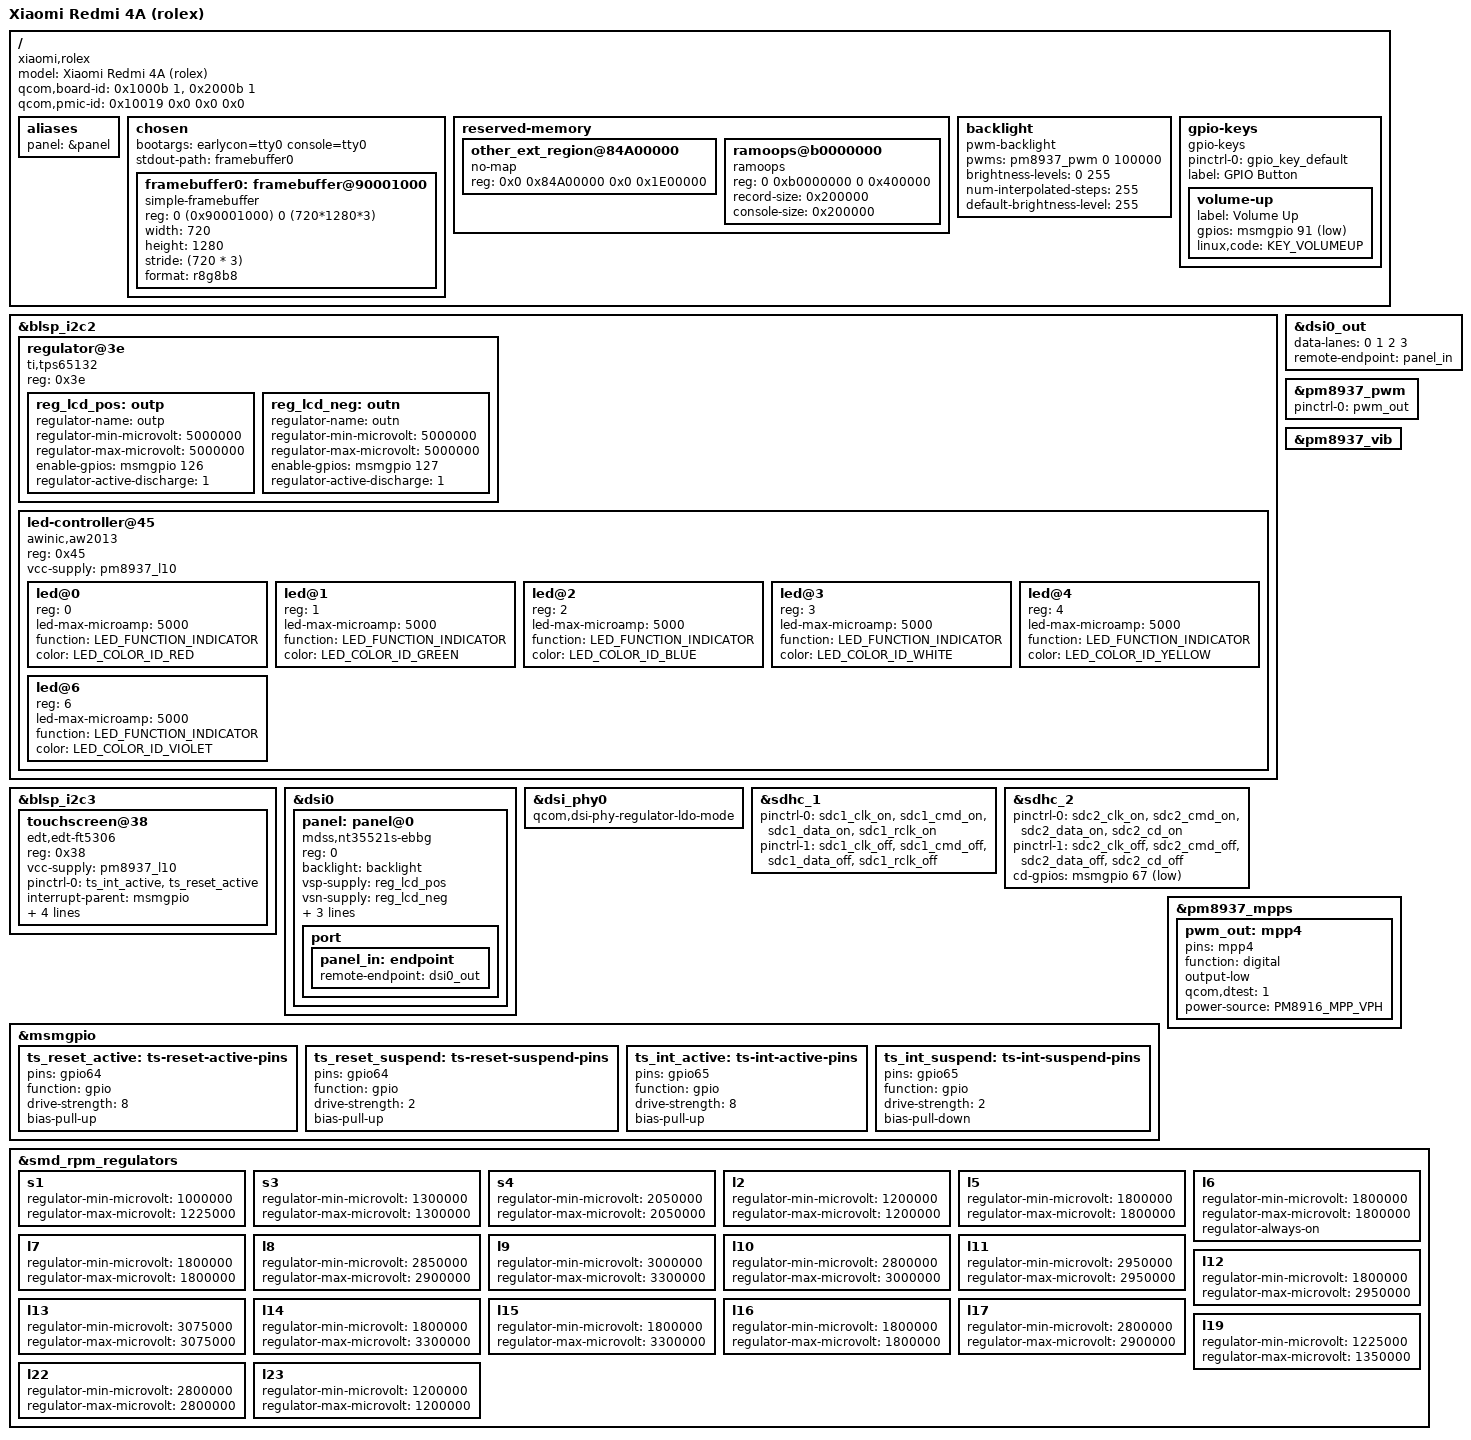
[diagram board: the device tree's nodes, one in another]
/dts-v1/;

#include "msm8917-pm8937.dtsi"
#include <dt-bindings/gpio/gpio.h>
#include <dt-bindings/leds/common.h>
#include <dt-bindings/pinctrl/qcom,pmic-mpp.h>

/ {
	model = "Xiaomi Redmi 4A (rolex)";
	compatible = "xiaomi,rolex", "qcom,msm8917";

	qcom,board-id= <0x1000b 1>, <0x2000b 1>;
	qcom,pmic-id = <0x10019 0x0 0x0 0x0>;

	aliases {
		panel = &panel;
	};

	chosen {
		bootargs = "earlycon=tty0 console=tty0";
		#address-cells = <2>;
		#size-cells = <2>;
		ranges;
		stdout-path = "framebuffer0";
		framebuffer0: framebuffer@90001000 {
			compatible = "simple-framebuffer";
			reg = <0 (0x90001000) 0 (720*1280*3)>;
			width = <720>;
			height = <1280>;
			stride = <(720 * 3)>;
			format = "r8g8b8";
			status= "okay";
		};
	};

	reserved-memory {
		/delete-node/other_ext_region@85b00000;

		other_ext_region@84A00000 {
			no-map;
			reg = <0x0 0x84A00000 0x0 0x1E00000>;
		};

		ramoops@b0000000 {
			compatible = "ramoops";
			reg = <0 0xb0000000 0 0x400000>;
			record-size = <0x200000>;
			console-size = <0x200000>;
		};
	};

	backlight: backlight {
		compatible = "pwm-backlight";
		pwms = <&pm8937_pwm 0 100000>;

		brightness-levels = <0 255>;
		num-interpolated-steps = <255>;
		default-brightness-level = <255>;
	};

	gpio-keys {
		compatible = "gpio-keys";

		pinctrl-names = "default";
		pinctrl-0 = <&gpio_key_default>;

		label = "GPIO Button";

		volume-up {
			label = "Volume Up";
			gpios = <&msmgpio 91 GPIO_ACTIVE_LOW>;
			linux,code = <KEY_VOLUMEUP>;
		};
	};
};

&blsp_i2c2 {
	status = "okay";
	regulator@3e {
		compatible = "ti,tps65132";
		reg = <0x3e>;

		//pinctrl-names = "default";
		//pinctrl-0 = <&reg_lcd_en_default>;

		reg_lcd_pos: outp {
			regulator-name = "outp";
			regulator-min-microvolt = <5000000>;
			regulator-max-microvolt = <5000000>;
			enable-gpios = <&msmgpio 126 GPIO_ACTIVE_HIGH>;
			regulator-active-discharge = <1>;
		};

		reg_lcd_neg: outn {
			regulator-name = "outn";
			regulator-min-microvolt = <5000000>;
			regulator-max-microvolt = <5000000>;
			enable-gpios = <&msmgpio 127 GPIO_ACTIVE_HIGH>;
			regulator-active-discharge = <1>;
		};
	};

	led-controller@45 {
		#address-cells = <1>;
		#size-cells = <0>;

		compatible = "awinic,aw2013";

		reg = <0x45>;

		vcc-supply = <&pm8937_l10>;

		led@0 {
			reg = <0>;
			led-max-microamp = <5000>;
			function = LED_FUNCTION_INDICATOR;
			color = <LED_COLOR_ID_RED>;
		};
		led@1 {
			reg = <1>;
			led-max-microamp = <5000>;
			function = LED_FUNCTION_INDICATOR;
			color = <LED_COLOR_ID_GREEN>;
		};
		led@2 {
			reg = <2>;
			led-max-microamp = <5000>;
			function = LED_FUNCTION_INDICATOR;
			color = <LED_COLOR_ID_BLUE>;
		};
		led@3 {
			reg = <3>;
			led-max-microamp = <5000>;
			function = LED_FUNCTION_INDICATOR;
			color = <LED_COLOR_ID_WHITE>;
		};

		led@4 {
			reg = <4>;
			led-max-microamp = <5000>;
			function = LED_FUNCTION_INDICATOR;
			color = <LED_COLOR_ID_YELLOW>;
		};
/*
		led@5 {
			reg = <5>;
			led-max-microamp = <5000>;
			function = LED_FUNCTION_INDICATOR;
			color = <LED_COLOR_ID_???>; // Cyan
		};
*/
		led@6 {
			reg = <6>;
			led-max-microamp = <5000>;
			function = LED_FUNCTION_INDICATOR;
			color = <LED_COLOR_ID_VIOLET>;
		};
	};
};

&blsp_i2c3 {
	status = "okay";

	touchscreen@38 {
		compatible = "edt,edt-ft5306", "edt,edt-ft5x06";
		reg = <0x38>;
		vcc-supply = <&pm8937_l10>;
		pinctrl-names = "default";
		pinctrl-0 = <&ts_int_active &ts_reset_active>;
		interrupt-parent = <&msmgpio>;
		interrupts = <65 0x2008>;
		reset-gpios = <&msmgpio 64 GPIO_ACTIVE_HIGH>;
		touchscreen-size-x = <720>;
		touchscreen-size-y = <1280>;
	};
};

&dsi0 {
	panel: panel@0 {
		compatible = "mdss,nt35521s-ebbg";
		reg = <0>;
		
		backlight = <&backlight>;
		vsp-supply = <&reg_lcd_pos>;
		vsn-supply = <&reg_lcd_neg>;
		reset-gpios = <&msmgpio 60 GPIO_ACTIVE_HIGH>;
		
		pinctrl-names = "default", "sleep";
		pinctrl-0 = <&mdss_dsi_active &mdss_te_active>;
		pinctrl-1 = <&mdss_dsi_suspend &mdss_te_suspend>;

		port {
			panel_in: endpoint {
				remote-endpoint = <&dsi0_out>;
			};
		};
	};
};

&dsi0_out {
	data-lanes = <0 1 2 3>;
	remote-endpoint = <&panel_in>;
};

&dsi_phy0 {
	qcom,dsi-phy-regulator-ldo-mode;
};

&sdhc_1 {
	status = "okay";

	pinctrl-names = "default", "sleep";
	pinctrl-0 = <&sdc1_clk_on &sdc1_cmd_on &sdc1_data_on &sdc1_rclk_on>;
	pinctrl-1 = <&sdc1_clk_off &sdc1_cmd_off &sdc1_data_off &sdc1_rclk_off>;
};

&sdhc_2 {
	status = "okay";

	pinctrl-names = "default", "sleep";
	pinctrl-0 = <&sdc2_clk_on &sdc2_cmd_on &sdc2_data_on &sdc2_cd_on>;
	pinctrl-1 = <&sdc2_clk_off &sdc2_cmd_off &sdc2_data_off &sdc2_cd_off>;

	cd-gpios = <&msmgpio 67 GPIO_ACTIVE_LOW>;
};

&msmgpio {
	ts_reset_active: ts-reset-active-pins {
		pins = "gpio64";
		function = "gpio";
		drive-strength = <8>;
		bias-pull-up;
	};

	ts_reset_suspend: ts-reset-suspend-pins {
		pins = "gpio64";
		function = "gpio";
		drive-strength = <2>;
		bias-pull-up;
	};
	ts_int_active: ts-int-active-pins {
		pins = "gpio65";
		function = "gpio";
		drive-strength = <8>;
		bias-pull-up;
	};

	ts_int_suspend: ts-int-suspend-pins {
		pins = "gpio65";
		function = "gpio";
		drive-strength = <2>;
		bias-pull-down;
	};
	/*
	reg_lcd_en_default: reg_lcd_en_default {
		pins = "gpio126", "gpio127";
		function = "gpio";
		drive-strength = <2>;
		bias-pull-down;
	};*/
};

&pm8937_pwm {
	status = "okay";
	pinctrl-names = "default";
	pinctrl-0 = <&pwm_out>;
};

&pm8937_vib {
	status = "okay";
};

&pm8937_mpps {
	pwm_out: mpp4 {
		pins = "mpp4";
		function = "digital";

		output-low;
		qcom,dtest = <1>;
		power-source = <PM8916_MPP_VPH>;
	};
};

&smd_rpm_regulators {
	s1 {
		regulator-min-microvolt = <1000000>;
		regulator-max-microvolt = <1225000>;
	};
	s3 {
		regulator-min-microvolt = <1300000>;
		regulator-max-microvolt = <1300000>;
	};
	s4 {
		regulator-min-microvolt = <2050000>;
		regulator-max-microvolt = <2050000>;
	};
	l2 {
		regulator-min-microvolt = <1200000>;
		regulator-max-microvolt = <1200000>;
	};
	l5 {
		regulator-min-microvolt = <1800000>;
		regulator-max-microvolt = <1800000>;
	};
	l6 {
		regulator-min-microvolt = <1800000>;
		regulator-max-microvolt = <1800000>;
		regulator-always-on;
	};
	l7 {
		regulator-min-microvolt = <1800000>;
		regulator-max-microvolt = <1800000>;
	};
	l8 {
		regulator-min-microvolt = <2850000>;
		regulator-max-microvolt = <2900000>;
	};
	l9 {
		regulator-min-microvolt = <3000000>;
		regulator-max-microvolt = <3300000>;
	};
	l10 {
		regulator-min-microvolt = <2800000>;
		regulator-max-microvolt = <3000000>;
	};
	l11 {
		regulator-min-microvolt = <2950000>;
		regulator-max-microvolt = <2950000>;
	};
	l12 {
		regulator-min-microvolt = <1800000>;
		regulator-max-microvolt = <2950000>;
	};
	l13 {
		regulator-min-microvolt = <3075000>;
		regulator-max-microvolt = <3075000>;
	};
	l14 {
		regulator-min-microvolt = <1800000>;
		regulator-max-microvolt = <3300000>;
	};
	l15 {
		regulator-min-microvolt = <1800000>;
		regulator-max-microvolt = <3300000>;
	};
	l16 {
		regulator-min-microvolt = <1800000>;
		regulator-max-microvolt = <1800000>;
	};
	l17 {
		regulator-min-microvolt = <2800000>;
		regulator-max-microvolt = <2900000>;
	};
	l19 {
		regulator-min-microvolt = <1225000>;
		regulator-max-microvolt = <1350000>;
	};
	l22 {
		regulator-min-microvolt = <2800000>;
		regulator-max-microvolt = <2800000>;
	};
	l23 {
		regulator-min-microvolt = <1200000>;
		regulator-max-microvolt = <1200000>;
	};
};
